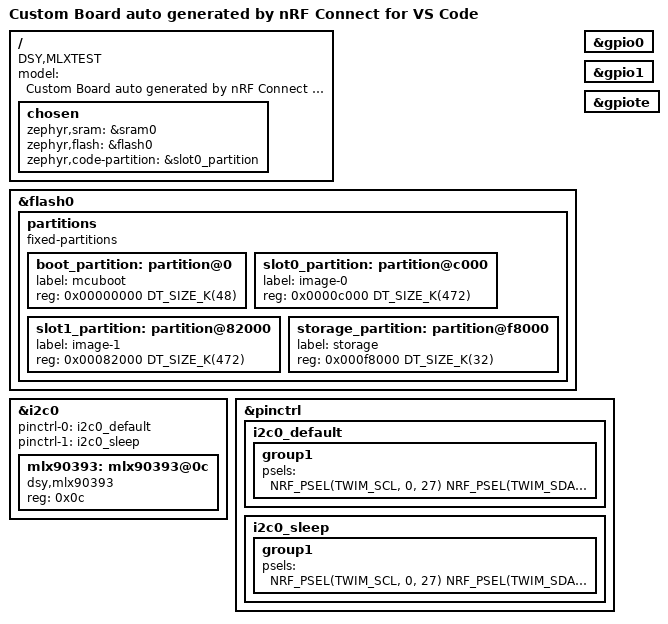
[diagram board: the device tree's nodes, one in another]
/dts-v1/;
#include <nordic/nrf52840_qiaa.dtsi>
#include "MLXTEST-pinctrl.dtsi"

/ {
	model = "Custom Board auto generated by nRF Connect for VS Code";
	compatible = "DSY,MLXTEST";

	chosen {
		zephyr,sram = &sram0;
		zephyr,flash = &flash0;
		zephyr,code-partition = &slot0_partition;
	};
};

&flash0 {
	partitions {
		compatible = "fixed-partitions";
		#address-cells = <1>;
		#size-cells = <1>;

		boot_partition: partition@0 {
			label = "mcuboot";
			reg = <0x00000000 DT_SIZE_K(48)>;
		};

		slot0_partition: partition@c000 {
			label = "image-0";
			reg = <0x0000c000 DT_SIZE_K(472)>;
		};

		slot1_partition: partition@82000 {
			label = "image-1";
			reg = <0x00082000 DT_SIZE_K(472)>;
		};

		storage_partition: partition@f8000 {
			label = "storage";
			reg = <0x000f8000 DT_SIZE_K(32)>;
		};
	};
};



&gpio0 {
	status = "okay";
};

&gpio1 {
	status = "okay";
};
&gpiote {
	status = "okay";
};

&i2c0 {
	status = "okay";
	pinctrl-0 = <&i2c0_default>;
	pinctrl-1 = <&i2c0_sleep>;
	pinctrl-names = "default", "sleep";

	/* SparkFun Qwiic MLX90393 默认 7-bit I2C 地址 0x0C */
	mlx90393: mlx90393@0c {
		compatible = "dsy,mlx90393";
		reg = <0x0c>;

		/* INT/TRIG 没接可以先不写；真接了再填 */
		/* int-gpios   = <&gpio0 10 GPIO_ACTIVE_HIGH>; */
		/* reset-gpios = <&gpio0 11 GPIO_ACTIVE_HIGH>; */
	};
};

&pinctrl {
	i2c0_default: i2c0_default {
		group1 {
			psels = <
				NRF_PSEL(TWIM_SCL, 0, 27)
				NRF_PSEL(TWIM_SDA, 0, 26)
			>;
		};
	};

	i2c0_sleep: i2c0_sleep {
		group1 {
			psels = <
				NRF_PSEL(TWIM_SCL, 0, 27)
				NRF_PSEL(TWIM_SDA, 0, 26)
			>;
		};
	};
};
